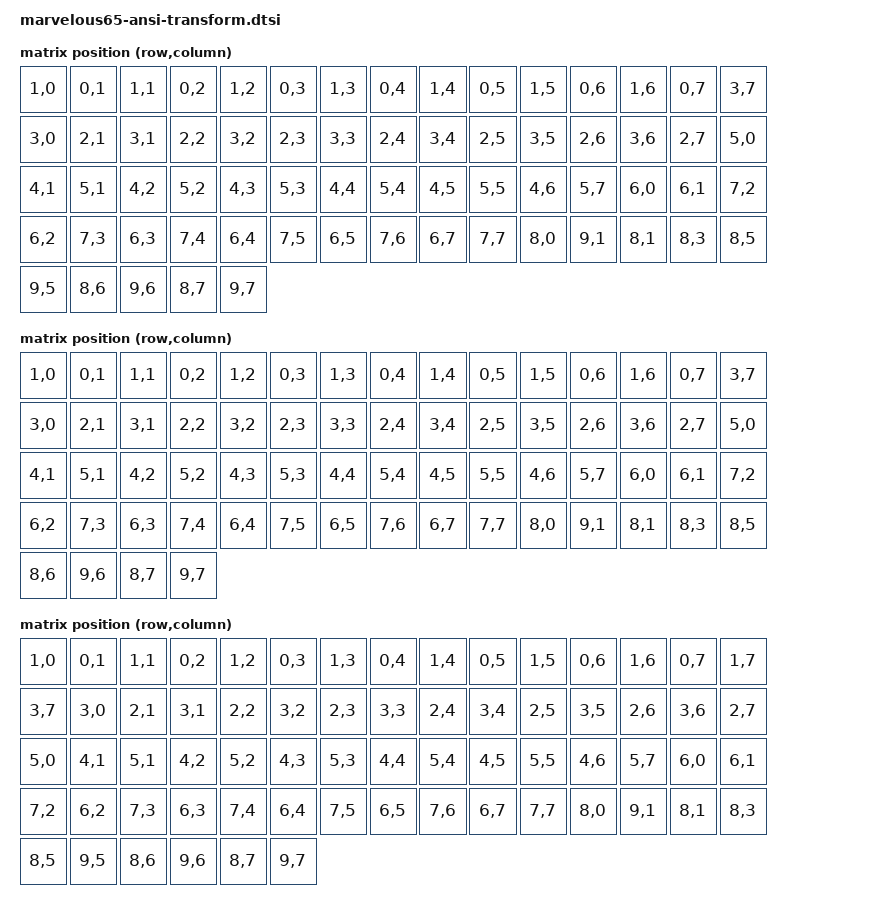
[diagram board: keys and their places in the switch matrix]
/ {
    ansi_transform_0: ansi_transform_0 {
        compatible = "zmk,matrix-transform";
        columns = <8>;
        rows = <10>;
        map = <
            RC(1,0) RC(0,1) RC(1,1) RC(0,2) RC(1,2) RC(0,3) RC(1,3) RC(0,4) RC(1,4) RC(0,5) RC(1,5) RC(0,6) RC(1,6) RC(0,7) RC(3,7)
            RC(3,0) RC(2,1) RC(3,1) RC(2,2) RC(3,2) RC(2,3) RC(3,3) RC(2,4) RC(3,4) RC(2,5) RC(3,5) RC(2,6) RC(3,6) RC(2,7) RC(5,0)
            RC(4,1) RC(5,1) RC(4,2) RC(5,2) RC(4,3) RC(5,3) RC(4,4) RC(5,4) RC(4,5) RC(5,5) RC(4,6) RC(5,7) RC(6,0) RC(6,1) RC(7,2)
            RC(6,2) RC(7,3) RC(6,3) RC(7,4) RC(6,4) RC(7,5) RC(6,5) RC(7,6) RC(6,7) RC(7,7) RC(8,0) RC(9,1) RC(8,1) RC(8,3) RC(8,5)
            RC(9,5) RC(8,6) RC(9,6) RC(8,7) RC(9,7)
        >;
    };

    ansi_transform_1: ansi_transform_1 {
        compatible = "zmk,matrix-transform";
        columns = <8>;
        rows = <10>;
        map = <
            RC(1,0) RC(0,1) RC(1,1) RC(0,2) RC(1,2) RC(0,3) RC(1,3) RC(0,4) RC(1,4) RC(0,5) RC(1,5) RC(0,6) RC(1,6) RC(0,7) RC(3,7)
            RC(3,0) RC(2,1) RC(3,1) RC(2,2) RC(3,2) RC(2,3) RC(3,3) RC(2,4) RC(3,4) RC(2,5) RC(3,5) RC(2,6) RC(3,6) RC(2,7) RC(5,0)
            RC(4,1) RC(5,1) RC(4,2) RC(5,2) RC(4,3) RC(5,3) RC(4,4) RC(5,4) RC(4,5) RC(5,5) RC(4,6) RC(5,7) RC(6,0) RC(6,1) RC(7,2)
            RC(6,2) RC(7,3) RC(6,3) RC(7,4) RC(6,4) RC(7,5) RC(6,5) RC(7,6) RC(6,7) RC(7,7) RC(8,0) RC(9,1) RC(8,1) RC(8,3) RC(8,5)
            RC(8,6) RC(9,6) RC(8,7) RC(9,7)
        >;
    };

    ansi_transform_2: ansi_transform_2 {
        compatible = "zmk,matrix-transform";
        columns = <8>;
        rows = <10>;
        map = <
            RC(1,0) RC(0,1) RC(1,1) RC(0,2) RC(1,2) RC(0,3) RC(1,3) RC(0,4) RC(1,4) RC(0,5) RC(1,5) RC(0,6) RC(1,6) RC(0,7) RC(1,7)
            RC(3,7) RC(3,0) RC(2,1) RC(3,1) RC(2,2) RC(3,2) RC(2,3) RC(3,3) RC(2,4) RC(3,4) RC(2,5) RC(3,5) RC(2,6) RC(3,6) RC(2,7)
            RC(5,0) RC(4,1) RC(5,1) RC(4,2) RC(5,2) RC(4,3) RC(5,3) RC(4,4) RC(5,4) RC(4,5) RC(5,5) RC(4,6) RC(5,7) RC(6,0) RC(6,1)
            RC(7,2) RC(6,2) RC(7,3) RC(6,3) RC(7,4) RC(6,4) RC(7,5) RC(6,5) RC(7,6) RC(6,7) RC(7,7) RC(8,0) RC(9,1) RC(8,1) RC(8,3)
            RC(8,5) RC(9,5) RC(8,6) RC(9,6) RC(8,7) RC(9,7)
        >;
    };

    ansi_transform_3: ansi_transform_3 {
        compatible = "zmk,matrix-transform";
        columns = <8>;
        rows = <10>;
        map = <
            RC(1,0) RC(0,1) RC(1,1) RC(0,2) RC(1,2) RC(0,3) RC(1,3) RC(0,4) RC(1,4) RC(0,5) RC(1,5) RC(0,6) RC(1,6) RC(0,7) RC(1,7)
            RC(3,7) RC(3,0) RC(2,1) RC(3,1) RC(2,2) RC(3,2) RC(2,3) RC(3,3) RC(2,4) RC(3,4) RC(2,5) RC(3,5) RC(2,6) RC(3,6) RC(2,7)
            RC(5,0) RC(4,1) RC(5,1) RC(4,2) RC(5,2) RC(4,3) RC(5,3) RC(4,4) RC(5,4) RC(4,5) RC(5,5) RC(4,6) RC(5,7) RC(6,0) RC(6,1)
            RC(7,2) RC(6,2) RC(7,3) RC(6,3) RC(7,4) RC(6,4) RC(7,5) RC(6,5) RC(7,6) RC(6,7) RC(7,7) RC(8,0) RC(9,1) RC(8,1) RC(8,3)
            RC(8,5) RC(8,6) RC(9,6) RC(8,7) RC(9,7)
        >;
    };

    ansi_transform_4: ansi_transform_4 {
        compatible = "zmk,matrix-transform";
        columns = <8>;
        rows = <10>;
        map = <
            RC(1,0) RC(0,1) RC(1,1) RC(0,2) RC(1,2) RC(0,3) RC(1,3) RC(0,4) RC(1,4) RC(0,5) RC(1,5) RC(0,6) RC(1,6) RC(0,7) RC(3,7)
            RC(3,0) RC(2,1) RC(3,1) RC(2,2) RC(3,2) RC(2,3) RC(3,3) RC(2,4) RC(3,4) RC(2,5) RC(3,5) RC(2,6) RC(3,6) RC(2,7) RC(5,0)
            RC(4,1) RC(5,1) RC(4,2) RC(5,2) RC(4,3) RC(5,3) RC(4,4) RC(5,4) RC(4,5) RC(5,5) RC(4,6) RC(5,7) RC(6,0) RC(6,1) RC(7,2)
            RC(6,2) RC(7,3) RC(6,3) RC(7,4) RC(6,4) RC(7,5) RC(6,5) RC(7,6) RC(6,7) RC(7,7) RC(8,0) RC(9,1) RC(8,1) RC(9,2) RC(8,3)
            RC(9,4) RC(8,5) RC(9,5) RC(8,6) RC(9,6) RC(8,7) RC(9,7)
        >;
    };

    ansi_transform_5: ansi_transform_5 {
        compatible = "zmk,matrix-transform";
        columns = <8>;
        rows = <10>;
        map = <
            RC(1,0) RC(0,1) RC(1,1) RC(0,2) RC(1,2) RC(0,3) RC(1,3) RC(0,4) RC(1,4) RC(0,5) RC(1,5) RC(0,6) RC(1,6) RC(0,7) RC(3,7)
            RC(3,0) RC(2,1) RC(3,1) RC(2,2) RC(3,2) RC(2,3) RC(3,3) RC(2,4) RC(3,4) RC(2,5) RC(3,5) RC(2,6) RC(3,6) RC(2,7) RC(5,0)
            RC(4,1) RC(5,1) RC(4,2) RC(5,2) RC(4,3) RC(5,3) RC(4,4) RC(5,4) RC(4,5) RC(5,5) RC(4,6) RC(5,7) RC(6,0) RC(6,1) RC(7,2)
            RC(6,2) RC(7,3) RC(6,3) RC(7,4) RC(6,4) RC(7,5) RC(6,5) RC(7,6) RC(6,7) RC(7,7) RC(8,0) RC(9,1) RC(8,1) RC(9,2) RC(8,3)
            RC(9,4) RC(8,5) RC(8,6) RC(9,6) RC(8,7) RC(9,7)
        >;
    };

    ansi_transform_6: ansi_transform_6 {
        compatible = "zmk,matrix-transform";
        columns = <8>;
        rows = <10>;
        map = <
            RC(1,0) RC(0,1) RC(1,1) RC(0,2) RC(1,2) RC(0,3) RC(1,3) RC(0,4) RC(1,4) RC(0,5) RC(1,5) RC(0,6) RC(1,6) RC(0,7) RC(1,7)
            RC(3,7) RC(3,0) RC(2,1) RC(3,1) RC(2,2) RC(3,2) RC(2,3) RC(3,3) RC(2,4) RC(3,4) RC(2,5) RC(3,5) RC(2,6) RC(3,6) RC(2,7)
            RC(5,0) RC(4,1) RC(5,1) RC(4,2) RC(5,2) RC(4,3) RC(5,3) RC(4,4) RC(5,4) RC(4,5) RC(5,5) RC(4,6) RC(5,7) RC(6,0) RC(6,1)
            RC(7,2) RC(6,2) RC(7,3) RC(6,3) RC(7,4) RC(6,4) RC(7,5) RC(6,5) RC(7,6) RC(6,7) RC(7,7) RC(8,0) RC(9,1) RC(8,1) RC(9,2)
            RC(8,3) RC(9,4) RC(8,5) RC(9,5) RC(8,6) RC(9,6) RC(8,7) RC(9,7)
        >;
    };

    ansi_transform_7: ansi_transform_7 {
        compatible = "zmk,matrix-transform";
        columns = <8>;
        rows = <10>;
        map = <
            RC(1,0) RC(0,1) RC(1,1) RC(0,2) RC(1,2) RC(0,3) RC(1,3) RC(0,4) RC(1,4) RC(0,5) RC(1,5) RC(0,6) RC(1,6) RC(0,7) RC(1,7)
            RC(3,7) RC(3,0) RC(2,1) RC(3,1) RC(2,2) RC(3,2) RC(2,3) RC(3,3) RC(2,4) RC(3,4) RC(2,5) RC(3,5) RC(2,6) RC(3,6) RC(2,7)
            RC(5,0) RC(4,1) RC(5,1) RC(4,2) RC(5,2) RC(4,3) RC(5,3) RC(4,4) RC(5,4) RC(4,5) RC(5,5) RC(4,6) RC(5,7) RC(6,0) RC(6,1)
            RC(7,2) RC(6,2) RC(7,3) RC(6,3) RC(7,4) RC(6,4) RC(7,5) RC(6,5) RC(7,6) RC(6,7) RC(7,7) RC(8,0) RC(9,1) RC(8,1) RC(9,2)
            RC(8,3) RC(9,4) RC(8,5) RC(8,6) RC(9,6) RC(8,7) RC(9,7)
        >;
    };

};
